AUTOSAR XML (schema 00049)
package /VehicleProject
  system System
    system mapping System_MPPNG
    root-software-compositions:
      root sw composition prototype ECU_Composition: software-composition=ECU_Composition
package /ECUCompositionTypes
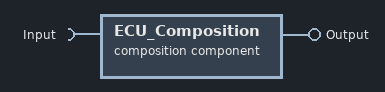
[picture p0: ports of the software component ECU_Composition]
  composition sw component type ECU_Composition
    provide port Output: provided-interface=Output
    require port Input: nonqueued-receiver-com-spec{data-element=LightSwitch, filter=data-filter-type=ALWAYS, init-value=0}, required-interface=Input
    component BSW_Handler: type=BSW_Handler
    component IoHwAb: type=IoHwAb
    component LightCtrl: type=LightCtrl
    connect IoHwAb.LightIntensityPort -> LightCtrl.LightIntensity
    delegate LightCtrl.Input <-> outer port Input
    delegate LightCtrl.Output <-> outer port Output
package /EndToEndProtections
  end to end protection set EndToEndConnections
